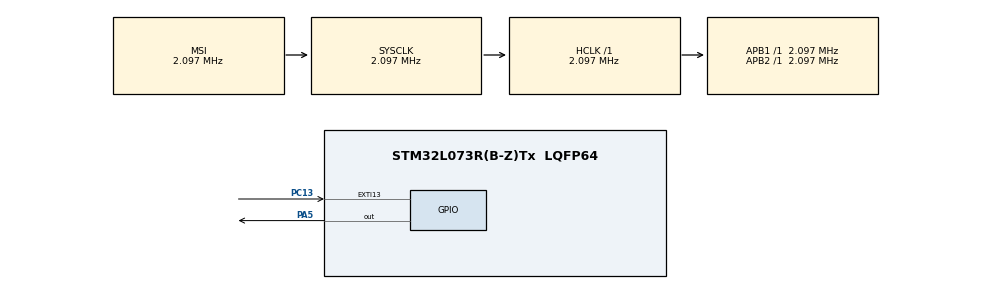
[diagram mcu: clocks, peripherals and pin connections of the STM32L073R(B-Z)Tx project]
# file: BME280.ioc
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Mcu.Family=STM32L0
Mcu.Name=STM32L073R(B-Z)Tx
Mcu.Package=LQFP64
NVIC.EXTI4_15_IRQn=true\:0\:0\:false\:false\:true\:true\:true\:true
NVIC.TIM2_IRQn=true\:0\:0\:false\:false\:true\:true\:true\:true
PA13.Mode=Serial_Wire
PA13.Signal=SYS_SWDIO
PA14.Mode=Serial_Wire
PA14.Signal=SYS_SWCLK
PA5.Signal=GPIO_Output
PC13.Signal=GPXTI13
PC14-OSC32_IN.Mode=LSE-External-Oscillator
PC14-OSC32_IN.Signal=RCC_OSC32_IN
PC15-OSC32_OUT.Mode=LSE-External-Oscillator
PC15-OSC32_OUT.Signal=RCC_OSC32_OUT
PH0-OSC_IN.Mode=HSE-External-Oscillator
PH0-OSC_IN.Signal=RCC_OSC_IN
PH1-OSC_OUT.Mode=HSE-External-Oscillator
PH1-OSC_OUT.Signal=RCC_OSC_OUT
ProjectManager.HeapSize=0x200
ProjectManager.StackSize=0x400
ProjectManager.TargetToolchain=STM32CubeIDE
RCC.AHBFreq_Value=2097000
RCC.APB1Freq_Value=2097000
RCC.APB1TimFreq_Value=2097000
RCC.APB2Freq_Value=2097000
RCC.APB2TimFreq_Value=2097000
RCC.HSE_VALUE=8000000
RCC.HSI16_VALUE=16000000
RCC.HSI48_VALUE=48000000
RCC.HSI_VALUE=16000000
RCC.MSI_VALUE=2097000
RCC.SYSCLKFreq_VALUE=2097000
RCC.VCOOutputFreq_Value=48000000
TIM2.AutoReloadPreload=TIM_AUTORELOAD_PRELOAD_ENABLE
TIM2.Period=999
TIM2.Prescaler=2000
VP_TIM2_VS_ClockSourceINT.Mode=Internal
board=custom

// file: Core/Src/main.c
/* USER CODE BEGIN Header */
/**
  ******************************************************************************
  * @file           : main.c
  * @brief          : Main program body
  ******************************************************************************
  * @attention
  *
  * Copyright (c) 2023 STMicroelectronics.
  * All rights reserved.
  *
  * This software is licensed under terms that can be found in the LICENSE file
  * in the root directory of this software component.
  * If no LICENSE file comes with this software, it is provided AS-IS.
  *
  ******************************************************************************
  */
/* USER CODE END Header */
#include "main.h"

TIM_HandleTypeDef htim2;

/* USER CODE BEGIN PV */
extern int tXindex;
/* USER CODE END PV */

void SystemClock_Config(void);
static void MX_GPIO_Init(void);
static void MX_TIM2_Init(void);

/* USER CODE BEGIN 0 */
void HAL_TIM_PeriodElapsedCallback(TIM_HandleTypeDef *htim){
	if(htim->Instance == TIM2){
		HAL_GPIO_TogglePin(GPIOA, GPIO_PIN_5);
	}
}

void HAL_GPIO_EXTI_Callback(uint8_t GPIO_Pin){
	if(*txIndex==499) *txIndex=999;
	else *txIndex=499;
}
/* USER CODE END 0 */

int main(void)
{

  /* MCU Configuration--------------------------------------------------------*/

  /* Reset of all peripherals, Initializes the Flash interface and the Systick. */
  HAL_Init();

  /* Configure the system clock */
  SystemClock_Config();

  /* Initialize all configured peripherals */
  MX_GPIO_Init();
  MX_TIM2_Init();

  /* Infinite loop */
  while (1)
  {

  }
}

void SystemClock_Config(void)
{
  RCC_OscInitTypeDef RCC_OscInitStruct = {0};
  RCC_ClkInitTypeDef RCC_ClkInitStruct = {0};

  /** Configure the main internal regulator output voltage
  */
  __HAL_PWR_VOLTAGESCALING_CONFIG(PWR_REGULATOR_VOLTAGE_SCALE1);

  /** Initializes the RCC Oscillators according to the specified parameters
  * in the RCC_OscInitTypeDef structure.
  */
  RCC_OscInitStruct.OscillatorType = RCC_OSCILLATORTYPE_MSI;
  RCC_OscInitStruct.MSIState = RCC_MSI_ON;
  RCC_OscInitStruct.MSICalibrationValue = 0;
  RCC_OscInitStruct.MSIClockRange = RCC_MSIRANGE_5;
  RCC_OscInitStruct.PLL.PLLState = RCC_PLL_NONE;
  if (HAL_RCC_OscConfig(&RCC_OscInitStruct) != HAL_OK)
  {
    Error_Handler();
  }

  /** Initializes the CPU, AHB and APB buses clocks
  */
  RCC_ClkInitStruct.ClockType = RCC_CLOCKTYPE_HCLK|RCC_CLOCKTYPE_SYSCLK
                              |RCC_CLOCKTYPE_PCLK1|RCC_CLOCKTYPE_PCLK2;
  RCC_ClkInitStruct.SYSCLKSource = RCC_SYSCLKSOURCE_MSI;
  RCC_ClkInitStruct.AHBCLKDivider = RCC_SYSCLK_DIV1;
  RCC_ClkInitStruct.APB1CLKDivider = RCC_HCLK_DIV1;
  RCC_ClkInitStruct.APB2CLKDivider = RCC_HCLK_DIV1;

  if (HAL_RCC_ClockConfig(&RCC_ClkInitStruct, FLASH_LATENCY_0) != HAL_OK)
  {
    Error_Handler();
  }
}

static void MX_TIM2_Init(void)
{

  TIM_ClockConfigTypeDef sClockSourceConfig = {0};
  TIM_MasterConfigTypeDef sMasterConfig = {0};

  htim2.Instance = TIM2;
  htim2.Init.Prescaler = 2000;
  htim2.Init.CounterMode = TIM_COUNTERMODE_UP;
  htim2.Init.Period = tX;
  htim2.Init.ClockDivision = TIM_CLOCKDIVISION_DIV1;
  htim2.Init.AutoReloadPreload = TIM_AUTORELOAD_PRELOAD_ENABLE;
  if (HAL_TIM_Base_Init(&htim2) != HAL_OK)
  {
    Error_Handler();
  }
  sClockSourceConfig.ClockSource = TIM_CLOCKSOURCE_INTERNAL;
  if (HAL_TIM_ConfigClockSource(&htim2, &sClockSourceConfig) != HAL_OK)
  {
    Error_Handler();
  }
  sMasterConfig.MasterOutputTrigger = TIM_TRGO_RESET;
  sMasterConfig.MasterSlaveMode = TIM_MASTERSLAVEMODE_DISABLE;
  if (HAL_TIMEx_MasterConfigSynchronization(&htim2, &sMasterConfig) != HAL_OK)
  {
    Error_Handler();
  }

}

static void MX_GPIO_Init(void)
{
  GPIO_InitTypeDef GPIO_InitStruct = {0};

  /* GPIO Ports Clock Enable */
  __HAL_RCC_GPIOC_CLK_ENABLE();
  __HAL_RCC_GPIOH_CLK_ENABLE();
  __HAL_RCC_GPIOA_CLK_ENABLE();

  /*Configure GPIO pin Output Level */
  HAL_GPIO_WritePin(GPIOA, GPIO_PIN_5, GPIO_PIN_RESET);

  /*Configure GPIO pin : PC13 */
  GPIO_InitStruct.Pin = GPIO_PIN_13;
  GPIO_InitStruct.Mode = GPIO_MODE_IT_RISING;
  GPIO_InitStruct.Pull = GPIO_NOPULL;
  HAL_GPIO_Init(GPIOC, &GPIO_InitStruct);

  /*Configure GPIO pin : PA5 */
  GPIO_InitStruct.Pin = GPIO_PIN_5;
  GPIO_InitStruct.Mode = GPIO_MODE_OUTPUT_PP;
  GPIO_InitStruct.Pull = GPIO_NOPULL;
  GPIO_InitStruct.Speed = GPIO_SPEED_FREQ_LOW;
  HAL_GPIO_Init(GPIOA, &GPIO_InitStruct);

  /* EXTI interrupt init*/
  HAL_NVIC_SetPriority(EXTI4_15_IRQn, 0, 0);
  HAL_NVIC_EnableIRQ(EXTI4_15_IRQn);

}

void Error_Handler(void)
{
  __disable_irq();
  while (1)
  {
  }
}
